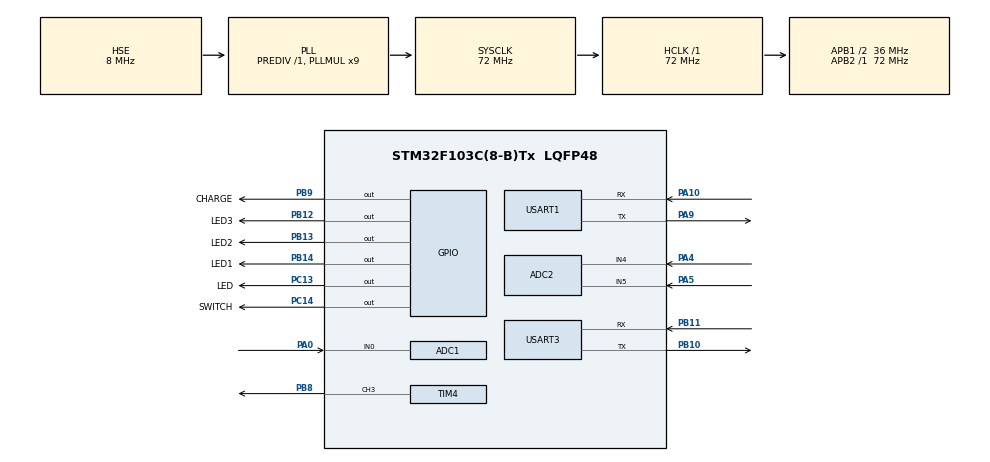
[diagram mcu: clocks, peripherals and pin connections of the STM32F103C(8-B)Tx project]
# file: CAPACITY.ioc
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ADC1.Channel-0\#ChannelRegularConversion=ADC_CHANNEL_0
ADC1.NbrOfConversionFlag=1
ADC1.Rank-0\#ChannelRegularConversion=1
ADC1.SamplingTime-0\#ChannelRegularConversion=ADC_SAMPLETIME_1CYCLE_5
ADC1.master=1
ADC2.Channel-0\#ChannelRegularConversion=ADC_CHANNEL_4
ADC2.NbrOfConversionFlag=1
ADC2.Rank-0\#ChannelRegularConversion=1
ADC2.SamplingTime-0\#ChannelRegularConversion=ADC_SAMPLETIME_1CYCLE_5
Dma.Request0=USART3_RX
Dma.USART3_RX.0.Direction=DMA_PERIPH_TO_MEMORY
Dma.USART3_RX.0.Instance=DMA1_Channel3
Dma.USART3_RX.0.MemDataAlignment=DMA_MDATAALIGN_BYTE
Dma.USART3_RX.0.MemInc=DMA_MINC_ENABLE
Dma.USART3_RX.0.Mode=DMA_NORMAL
Dma.USART3_RX.0.PeriphDataAlignment=DMA_PDATAALIGN_BYTE
Dma.USART3_RX.0.PeriphInc=DMA_PINC_DISABLE
Dma.USART3_RX.0.Priority=DMA_PRIORITY_LOW
FREERTOS.INCLUDE_vTaskDelayUntil=1
FREERTOS.Tasks01=defaultTask,0,128,StartDefaultTask,Default,NULL
Mcu.Family=STM32F1
Mcu.Name=STM32F103C(8-B)Tx
Mcu.Package=LQFP48
NVIC.DMA1_Channel3_IRQn=true\:5\:0\:false\:false\:true\:true\:false\:true
NVIC.PriorityGroup=NVIC_PRIORITYGROUP_4
NVIC.TIM3_IRQn=true\:0\:0\:false\:false\:true\:false\:false\:true
NVIC.TimeBase=TIM3_IRQn
NVIC.TimeBaseIP=TIM3
NVIC.USART1_IRQn=true\:5\:0\:false\:false\:true\:true\:true\:true
NVIC.USART3_IRQn=true\:5\:0\:false\:false\:true\:true\:true\:true
PA0-WKUP.Signal=ADCx_IN0
PA10.Mode=Asynchronous
PA10.Signal=USART1_RX
PA13.Mode=Serial_Wire
PA13.Signal=SYS_JTMS-SWDIO
PA14.Mode=Serial_Wire
PA14.Signal=SYS_JTCK-SWCLK
PA4.Signal=ADCx_IN4
PA5.Signal=ADCx_IN5
PA9.Mode=Asynchronous
PA9.Signal=USART1_TX
PB10.Mode=Asynchronous
PB10.Signal=USART3_TX
PB11.Mode=Asynchronous
PB11.Signal=USART3_RX
PB12.GPIO_Label=LED3
PB12.GPIO_ModeDefaultOutputPP=GPIO_MODE_OUTPUT_PP
PB12.GPIO_PuPd=GPIO_NOPULL
PB12.GPIO_Speed=GPIO_SPEED_FREQ_HIGH
PB12.PinState=GPIO_PIN_RESET
PB12.Signal=GPIO_Output
PB13.GPIO_Label=LED2
PB13.GPIO_ModeDefaultOutputPP=GPIO_MODE_OUTPUT_PP
PB13.GPIO_PuPd=GPIO_NOPULL
PB13.GPIO_Speed=GPIO_SPEED_FREQ_HIGH
PB13.PinState=GPIO_PIN_RESET
PB13.Signal=GPIO_Output
PB14.GPIO_Label=LED1
PB14.GPIO_ModeDefaultOutputPP=GPIO_MODE_OUTPUT_PP
PB14.GPIO_PuPd=GPIO_NOPULL
PB14.GPIO_Speed=GPIO_SPEED_FREQ_HIGH
PB14.PinState=GPIO_PIN_RESET
PB14.Signal=GPIO_Output
PB8.Signal=S_TIM4_CH3
PB9.GPIO_Label=CHARGE
PB9.GPIO_ModeDefaultOutputPP=GPIO_MODE_OUTPUT_PP
PB9.GPIO_PuPd=GPIO_NOPULL
PB9.GPIO_Speed=GPIO_SPEED_FREQ_HIGH
PB9.PinState=GPIO_PIN_RESET
PB9.Signal=GPIO_Output
PC13-TAMPER-RTC.GPIO_Label=LED
PC13-TAMPER-RTC.GPIO_ModeDefaultOutputPP=GPIO_MODE_OUTPUT_PP
PC13-TAMPER-RTC.GPIO_PuPd=GPIO_NOPULL
PC13-TAMPER-RTC.GPIO_Speed=GPIO_SPEED_FREQ_HIGH
PC13-TAMPER-RTC.PinState=GPIO_PIN_SET
PC13-TAMPER-RTC.Signal=GPIO_Output
PC14-OSC32_IN.GPIO_Label=SWITCH
PC14-OSC32_IN.GPIO_ModeDefaultOutputPP=GPIO_MODE_OUTPUT_PP
PC14-OSC32_IN.GPIO_Speed=GPIO_SPEED_FREQ_HIGH
PC14-OSC32_IN.PinState=GPIO_PIN_RESET
PC14-OSC32_IN.Signal=GPIO_Output
PD0-OSC_IN.Mode=HSE-External-Oscillator
PD0-OSC_IN.Signal=RCC_OSC_IN
PD1-OSC_OUT.Mode=HSE-External-Oscillator
PD1-OSC_OUT.Signal=RCC_OSC_OUT
ProjectManager.HeapSize=0x400
ProjectManager.StackSize=0x800
ProjectManager.TargetToolchain=MDK-ARM V5
RCC.ADCPresc=RCC_ADCPCLK2_DIV6
RCC.AHBFreq_Value=72000000
RCC.APB1CLKDivider=RCC_HCLK_DIV2
RCC.APB1Freq_Value=36000000
RCC.APB1TimFreq_Value=72000000
RCC.APB2Freq_Value=72000000
RCC.APB2TimFreq_Value=72000000
RCC.HCLKFreq_Value=72000000
RCC.PLLMUL=RCC_PLL_MUL9
RCC.PLLSourceVirtual=RCC_PLLSOURCE_HSE
RCC.SYSCLKFreq_VALUE=72000000
RCC.SYSCLKSource=RCC_SYSCLKSOURCE_PLLCLK
RCC.USBFreq_Value=72000000
SH.ADCx_IN0.0=ADC1_IN0,IN0
SH.ADCx_IN4.0=ADC2_IN4,IN4
SH.ADCx_IN5.0=ADC2_IN5,IN5
SH.S_TIM4_CH3.0=TIM4_CH3,PWM Generation3 CH3
TIM4.Channel-PWM\ Generation3\ CH3=TIM_CHANNEL_3
TIM4.Period=6000
TIM4.Prescaler=12
USART1.VirtualMode=VM_ASYNC
USART3.VirtualMode=VM_ASYNC
VP_FREERTOS_VS_CMSIS_V1.Mode=CMSIS_V1
VP_SYS_VS_tim3.Mode=TIM3
VP_TIM4_VS_ClockSourceINT.Mode=Internal
board=custom

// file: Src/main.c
/* USER CODE BEGIN Header */
/**
  ******************************************************************************
  * @file           : main.c
  * @brief          : Main program body
  ******************************************************************************
  * @attention
  *
  * <h2><center>&copy; Copyright (c) 2019 STMicroelectronics.
  * All rights reserved.</center></h2>
  *
  * This software component is licensed by ST under Ultimate Liberty license
  * SLA0044, the "License"; You may not use this file except in compliance with
  * the License. You may obtain a copy of the License at:
  *                             www.st.com/SLA0044
  *
  ******************************************************************************
  */
/* USER CODE END Header */

#include "main.h"
#include "cmsis_os.h"
#include "adc.h"
#include "dma.h"
#include "tim.h"
#include "usart.h"
#include "gpio.h"

void SystemClock_Config(void);
void MX_FREERTOS_Init(void);

int main(void)
{

  /* MCU Configuration--------------------------------------------------------*/

  /* Reset of all peripherals, Initializes the Flash interface and the Systick. */
  HAL_Init();

  /* Configure the system clock */
  SystemClock_Config();

  /* Initialize all configured peripherals */
  MX_GPIO_Init();
  MX_DMA_Init();
  MX_ADC1_Init();
  MX_TIM4_Init();
  MX_USART1_UART_Init();
  MX_USART3_UART_Init();
  MX_ADC2_Init();

  /* Call init function for freertos objects (in freertos.c) */
  MX_FREERTOS_Init();

  /* Start scheduler */
  osKernelStart();

  /* We should never get here as control is now taken by the scheduler */

  /* Infinite loop */
  while (1)
  {

  }
}

void SystemClock_Config(void)
{
  RCC_OscInitTypeDef RCC_OscInitStruct = {0};
  RCC_ClkInitTypeDef RCC_ClkInitStruct = {0};
  RCC_PeriphCLKInitTypeDef PeriphClkInit = {0};

  /** Initializes the CPU, AHB and APB busses clocks
  */
  RCC_OscInitStruct.OscillatorType = RCC_OSCILLATORTYPE_HSE;
  RCC_OscInitStruct.HSEState = RCC_HSE_ON;
  RCC_OscInitStruct.HSEPredivValue = RCC_HSE_PREDIV_DIV1;
  RCC_OscInitStruct.HSIState = RCC_HSI_ON;
  RCC_OscInitStruct.PLL.PLLState = RCC_PLL_ON;
  RCC_OscInitStruct.PLL.PLLSource = RCC_PLLSOURCE_HSE;
  RCC_OscInitStruct.PLL.PLLMUL = RCC_PLL_MUL9;
  if (HAL_RCC_OscConfig(&RCC_OscInitStruct) != HAL_OK)
  {
    Error_Handler();
  }
  /** Initializes the CPU, AHB and APB busses clocks
  */
  RCC_ClkInitStruct.ClockType = RCC_CLOCKTYPE_HCLK|RCC_CLOCKTYPE_SYSCLK
                              |RCC_CLOCKTYPE_PCLK1|RCC_CLOCKTYPE_PCLK2;
  RCC_ClkInitStruct.SYSCLKSource = RCC_SYSCLKSOURCE_PLLCLK;
  RCC_ClkInitStruct.AHBCLKDivider = RCC_SYSCLK_DIV1;
  RCC_ClkInitStruct.APB1CLKDivider = RCC_HCLK_DIV2;
  RCC_ClkInitStruct.APB2CLKDivider = RCC_HCLK_DIV1;

  if (HAL_RCC_ClockConfig(&RCC_ClkInitStruct, FLASH_LATENCY_2) != HAL_OK)
  {
    Error_Handler();
  }
  PeriphClkInit.PeriphClockSelection = RCC_PERIPHCLK_ADC;
  PeriphClkInit.AdcClockSelection = RCC_ADCPCLK2_DIV6;
  if (HAL_RCCEx_PeriphCLKConfig(&PeriphClkInit) != HAL_OK)
  {
    Error_Handler();
  }
}

void HAL_TIM_PeriodElapsedCallback(TIM_HandleTypeDef *htim)
{
  if (htim->Instance == TIM3) {
    HAL_IncTick();
  }
}

void Error_Handler(void)
{
}

/************************ (C) COPYRIGHT STMicroelectronics *****END OF FILE****/

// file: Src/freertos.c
/* USER CODE BEGIN Header */
/**
  ******************************************************************************
  * File Name          : freertos.c
  * Description        : Code for freertos applications
  ******************************************************************************
  * @attention
  *
  * <h2><center>&copy; Copyright (c) 2019 STMicroelectronics.
  * All rights reserved.</center></h2>
  *
  * This software component is licensed by ST under Ultimate Liberty license
  * SLA0044, the "License"; You may not use this file except in compliance with
  * the License. You may obtain a copy of the License at:
  *                             www.st.com/SLA0044
  *
  ******************************************************************************
  */
/* USER CODE END Header */

#include "FreeRTOS.h"
#include "task.h"
#include "main.h"
#include "cmsis_os.h"

/* USER CODE BEGIN Includes */
#include "rtos.h"

/* USER CODE END Includes */

osThreadId defaultTaskHandle;

void StartDefaultTask(void const * argument);

void MX_FREERTOS_Init(void); /* (MISRA C 2004 rule 8.1) */

void MX_FREERTOS_Init(void) {

  /* Create the thread(s) */
  /* definition and creation of defaultTask */
  osThreadDef(defaultTask, StartDefaultTask, osPriorityNormal, 0, 128);
  defaultTaskHandle = osThreadCreate(osThread(defaultTask), NULL);

}

void StartDefaultTask(void const * argument)
{

  /* USER CODE BEGIN StartDefaultTask */
	taskENTER_CRITICAL();
	start();
	traceTASK_DELETE(NULL);
	taskEXIT_CRITICAL();

  /* Infinite loop */
  for(;;)
  {
    osDelay(1);
  }
  /* USER CODE END StartDefaultTask */
}

/************************ (C) COPYRIGHT STMicroelectronics *****END OF FILE****/
